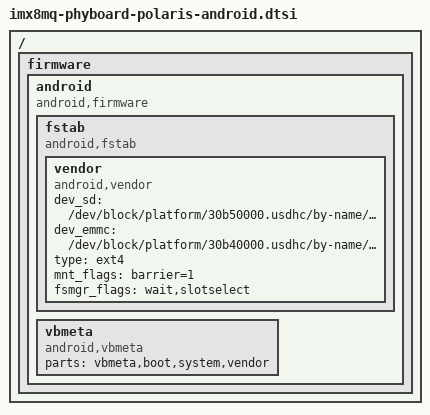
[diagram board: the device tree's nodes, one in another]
/*
 * Copyright (C) 2019 emteria GmbH
 * Author: Igor Kalkov <ik@emteria.com>
 *
 * This program is free software; you can redistribute it and/or
 * modify it under the terms of the GNU General Public License
 * as published by the Free Software Foundation; either version 2
 * of the License, or (at your option) any later version.
 *
 * This program is distributed in the hope that it will be useful,
 * but WITHOUT ANY WARRANTY; without even the implied warranty of
 * MERCHANTABILITY or FITNESS FOR A PARTICULAR PURPOSE.  See the
 * GNU General Public License for more details.
 */

/ {
	firmware {
		android {
			compatible = "android,firmware";
			fstab {
				compatible = "android,fstab";
				vendor {
					compatible = "android,vendor";
					/* sd card node which used if androidboot.storage_type=sd */
					dev_sd = "/dev/block/platform/30b50000.usdhc/by-name/vendor";
					/* emmc node which used if androidboot.storage_type=emmc */
					dev_emmc = "/dev/block/platform/30b40000.usdhc/by-name/vendor";
					type = "ext4";
					mnt_flags = "barrier=1";
					fsmgr_flags = "wait,slotselect";
				};
			};
			vbmeta {
				/*we need use FirstStageMountVBootV2 if we enable avb*/
				compatible = "android,vbmeta";
				/*parts means the partition witch can be mount in first stage*/
				parts = "vbmeta,boot,system,vendor";
			};
		};
	};
};
